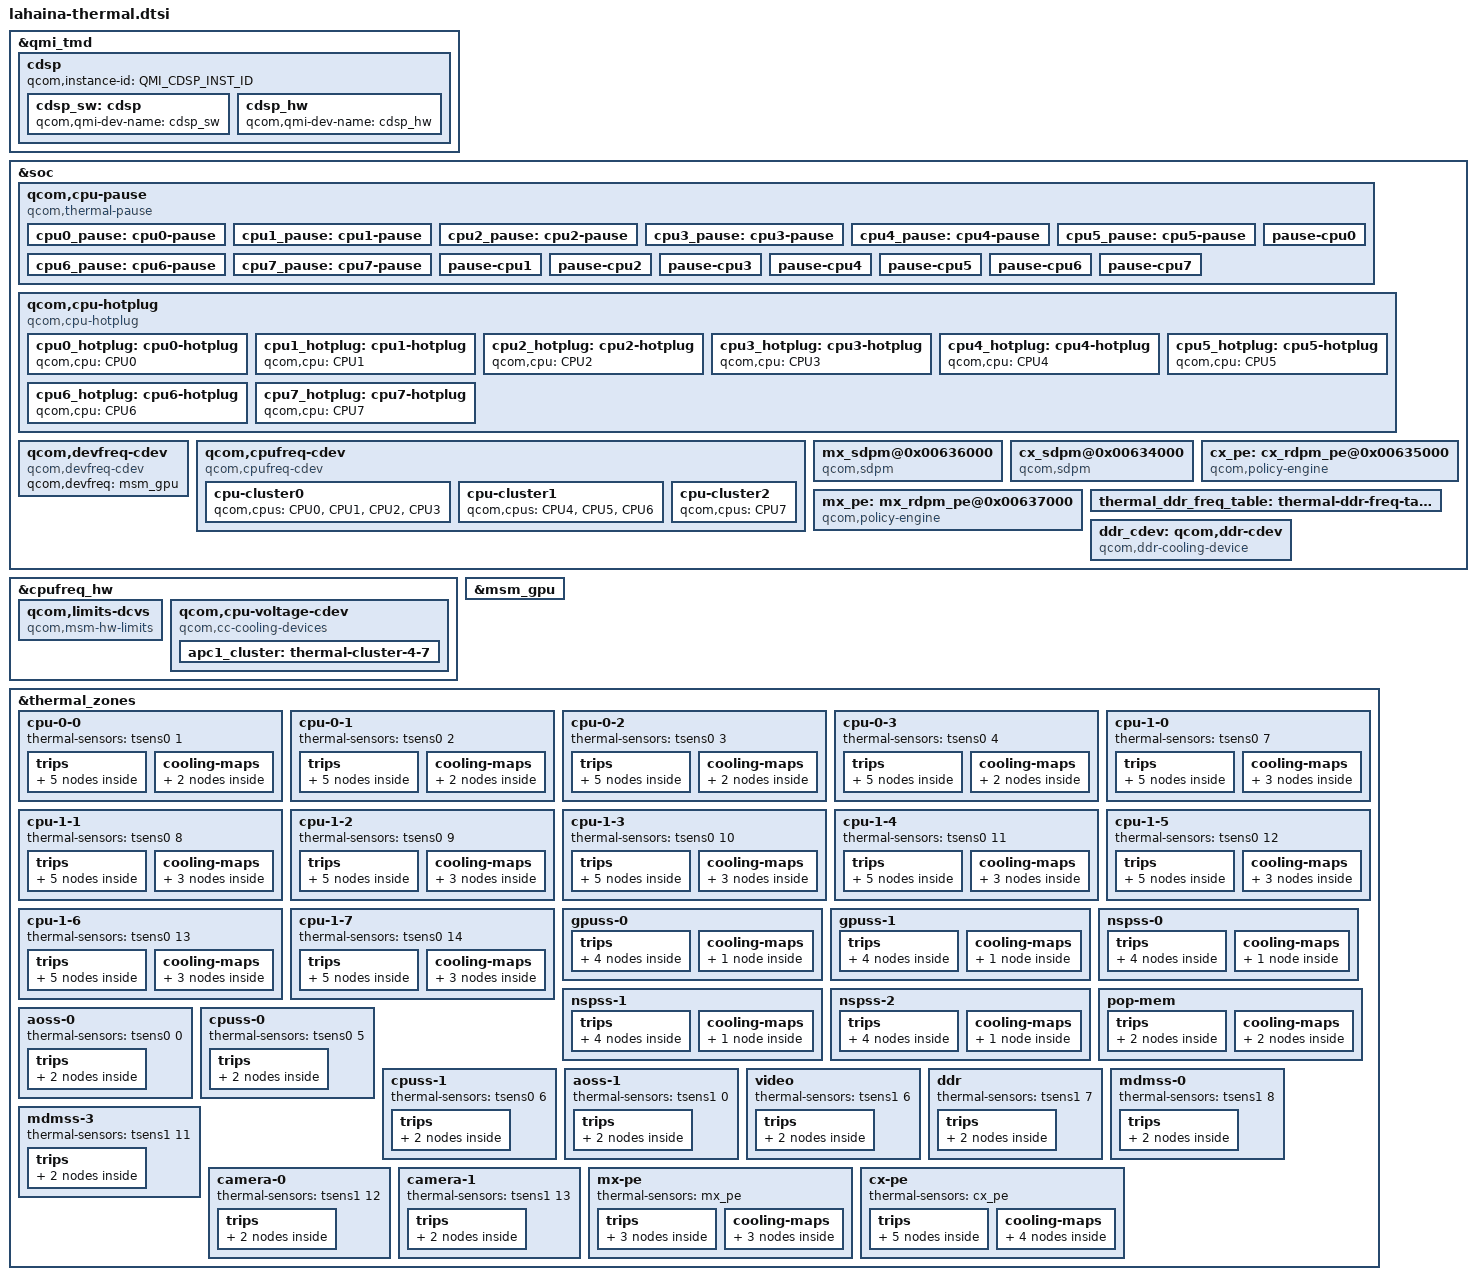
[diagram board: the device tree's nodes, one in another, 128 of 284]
// SPDX-License-Identifier: BSD-3-Clause
/*
 * Copyright (c) Qualcomm Technologies, Inc. and/or its subsidiaries.
 */

#include <dt-bindings/thermal/thermal_qti.h>
#include "lahaina-thermal-modem.dtsi"

&qmi_tmd {
	cdsp {
		qcom,instance-id = <QMI_CDSP_INST_ID>;

		cdsp_sw: cdsp {
			qcom,qmi-dev-name = "cdsp_sw";
			#cooling-cells = <2>;
		};

		cdsp_hw: cdsp_hw {
			qcom,qmi-dev-name = "cdsp_hw";
			#cooling-cells = <2>;
		};
	};
};

&soc {
	qcom,cpu-pause {
		compatible = "qcom,thermal-pause";
		cpu0_pause: cpu0-pause {
			qcom,cpus = <&CPU0>;
			qcom,cdev-alias = "thermal-pause-1";
			#cooling-cells = <2>;
		};

		cpu1_pause: cpu1-pause {
			qcom,cpus = <&CPU1>;
			qcom,cdev-alias = "thermal-pause-2";
			#cooling-cells = <2>;
		};

		cpu2_pause: cpu2-pause {
			qcom,cpus = <&CPU2>;
			qcom,cdev-alias = "thermal-pause-4";
			#cooling-cells = <2>;
		};

		cpu3_pause: cpu3-pause {
			qcom,cpus = <&CPU3>;
			qcom,cdev-alias = "thermal-pause-8";
			#cooling-cells = <2>;
		};

		cpu4_pause: cpu4-pause {
			qcom,cpus = <&CPU4>;
			qcom,cdev-alias = "thermal-pause-10";
			#cooling-cells = <2>;
		};

		cpu5_pause: cpu5-pause {
			qcom,cpus = <&CPU5>;
			qcom,cdev-alias = "thermal-pause-20";
			#cooling-cells = <2>;
		};

		cpu6_pause: cpu6-pause {
			qcom,cpus = <&CPU6>;
			qcom,cdev-alias = "thermal-pause-40";
			#cooling-cells = <2>;
		};

		cpu7_pause: cpu7-pause {
			qcom,cpus = <&CPU7>;
			qcom,cdev-alias = "thermal-pause-80";
			#cooling-cells = <2>;
		};

		/* Thermal-engine cooling devices */
		pause-cpu0 {
			qcom,cpus = <&CPU0>;
			qcom,cdev-alias = "pause-cpu0";
		};

		pause-cpu1 {
			qcom,cpus = <&CPU1>;
			qcom,cdev-alias = "pause-cpu1";
		};

		pause-cpu2 {
			qcom,cpus = <&CPU2>;
			qcom,cdev-alias = "pause-cpu2";
		};

		pause-cpu3 {
			qcom,cpus = <&CPU3>;
			qcom,cdev-alias = "pause-cpu3";
		};

		pause-cpu4 {
			qcom,cpus = <&CPU4>;
			qcom,cdev-alias = "pause-cpu4";
		};

		pause-cpu5 {
			qcom,cpus = <&CPU5>;
			qcom,cdev-alias = "pause-cpu5";
		};

		pause-cpu6 {
			qcom,cpus = <&CPU6>;
			qcom,cdev-alias = "pause-cpu6";
		};

		pause-cpu7 {
			qcom,cpus = <&CPU7>;
			qcom,cdev-alias = "pause-cpu7";
		};
	};

	qcom,cpu-hotplug {
		compatible = "qcom,cpu-hotplug";
		cpu0_hotplug: cpu0-hotplug {
			qcom,cpu = <&CPU0>;
			#cooling-cells = <2>;
		};

		cpu1_hotplug: cpu1-hotplug {
			qcom,cpu = <&CPU1>;
			#cooling-cells = <2>;
		};

		cpu2_hotplug: cpu2-hotplug {
			qcom,cpu = <&CPU2>;
			#cooling-cells = <2>;
		};

		cpu3_hotplug: cpu3-hotplug {
			qcom,cpu = <&CPU3>;
			#cooling-cells = <2>;
		};

		cpu4_hotplug: cpu4-hotplug {
			qcom,cpu = <&CPU4>;
			#cooling-cells = <2>;
		};

		cpu5_hotplug: cpu5-hotplug {
			qcom,cpu = <&CPU5>;
			#cooling-cells = <2>;
		};

		cpu6_hotplug: cpu6-hotplug {
			qcom,cpu = <&CPU6>;
			#cooling-cells = <2>;
		};

		cpu7_hotplug: cpu7-hotplug {
			qcom,cpu = <&CPU7>;
			#cooling-cells = <2>;
		};
	};

	qcom,devfreq-cdev {
		compatible = "qcom,devfreq-cdev";
		qcom,devfreq = <&msm_gpu>;
	};

	qcom,cpufreq-cdev {
		compatible = "qcom,cpufreq-cdev";
		cpu-cluster0 {
			qcom,cpus = <&CPU0 &CPU1 &CPU2 &CPU3>;
		};

		cpu-cluster1 {
			qcom,cpus = <&CPU4 &CPU5 &CPU6>;
		};

		cpu-cluster2 {
			qcom,cpus = <&CPU7>;
		};
	};

	mx_sdpm@0x00636000 {
		compatible = "qcom,sdpm";
		reg = <0x00636000 0x1000>;
		clock-names = "cam_cc_ipe", "video_cc_mvs0", "gcc_gp1";
		clocks = <&camcc CAM_CC_IPE_0_CLK_SRC>,
			<&videocc VIDEO_CC_MVS0_CLK_SRC>,
			<&gcc GCC_GP1_CLK_SRC>;
		cam_cc_ipe-supply = <&cam_cc_ipe_0_gdsc>;
		video_cc_mvs0-supply = <&video_cc_mvs0_gdsc>;
		csr-id = <1 3 5>;
	};

	cx_sdpm@0x00634000 {
		compatible = "qcom,sdpm";
		reg = <0x00634000 0x1000>;
		clock-names = "cam_cc_csi0phytiimer", "ufs_phy";
		clocks = <&camcc CAM_CC_CSI0PHYTIMER_CLK_SRC>,
			<&gcc GCC_UFS_PHY_AXI_CLK_SRC>;
		cam_cc_csi0phytiimer-supply = <&cam_cc_ipe_0_gdsc>;
		csr-id = <5 7>;
	};

	mx_pe: mx_rdpm_pe@0x00637000 {
		compatible = "qcom,policy-engine";
		#thermal-sensor-cells = <0>;
		reg = <0x00637000 0x1000>;
		interrupts = <GIC_SPI 237 IRQ_TYPE_LEVEL_HIGH>;
	};

	cx_pe: cx_rdpm_pe@0x00635000 {
		compatible = "qcom,policy-engine";
		#thermal-sensor-cells = <0>;
		reg = <0x00635000 0x1000>;
		interrupts = <GIC_SPI 243 IRQ_TYPE_LEVEL_HIGH>;
	};

	thermal_ddr_freq_table: thermal-ddr-freq-table {
		qcom,freq-tbl = <0>,
				<1720000>,
				<2086000>,
				<2597000>,
				<2929000>,
				<3879000>,
				<5161000>,
				<5931000>,
				<6515000>,
				<7980000>,
				<8136000>,
				<10437000>,
				<12191000>;
	};

	ddr_cdev: qcom,ddr-cdev {
		compatible = "qcom,ddr-cooling-device";
		#cooling-cells = <2>;
		qcom,bus-width = <4>;
		qcom,freq-table = <&thermal_ddr_freq_table>;
		interconnects = <&mc_virt MASTER_LLCC &mc_virt SLAVE_EBI1>;
	};
};

&cpufreq_hw {
	qcom,limits-dcvs {
		compatible = "qcom,msm-hw-limits";
		isens_vref_0p8-supply = <&pm8350_l5_ao>;
		isens-vref-0p8-settings = <880000 880000 30000>;
		isens_vref_1p8-supply = <&pm8350c_l1_ao>;
		isens-vref-1p8-settings = <1800000 1800000 20000>;
	};

	qcom,cpu-voltage-cdev {
		compatible = "qcom,cc-cooling-devices";
		apc1_cluster: thermal-cluster-4-7 {
			qcom,cluster0 = <&CPU4 &CPU5 &CPU6>;
			qcom,cluster1 = <&CPU7>;
			#cooling-cells = <2>;
		};
	};
};

&msm_gpu {
	#cooling-cells = <2>;
};

&thermal_zones {
	cpu-0-0 {
		thermal-sensors = <&tsens0 1>;
		trips {
			active-config0 {
				temperature = <125000>;
				hysteresis = <1000>;
				type = "passive";
			};

			thermal-hal-config {
				temperature = <95000>;
				hysteresis = <5000>;
				type = "passive";
			};

			cpu00_config: cpu00-config {
				temperature = <110000>;
				hysteresis = <10000>;
				type = "passive";
			};

			cpu00_config1: cpu00-config1 {
				temperature = <112000>;
				hysteresis = <12000>;
				type = "passive";
			};

			reset-mon-cfg {
				temperature = <115000>;
				hysteresis = <0>;
				type = "hot";
			};
		};

		cooling-maps {
			cpu00_cdev {
				trip = <&cpu00_config>;
				cooling-device = <&cpu0_pause 0 1>;
			};

			cpu00_cdev2 {
				trip = <&cpu00_config1>;
				cooling-device = <&cpu0_hotplug 0 1>;
			};
		};
	};

	cpu-0-1 {
		thermal-sensors = <&tsens0 2>;
		trips {
			active-config0 {
				temperature = <125000>;
				hysteresis = <1000>;
				type = "passive";
			};

			thermal-hal-config {
				temperature = <95000>;
				hysteresis = <5000>;
				type = "passive";
			};

			cpu01_config: cpu01-config {
				temperature = <110000>;
				hysteresis = <10000>;
				type = "passive";
			};

			cpu01_config1: cpu01-config1 {
				temperature = <112000>;
				hysteresis = <12000>;
				type = "passive";
			};

			reset-mon-cfg {
				temperature = <115000>;
				hysteresis = <0>;
				type = "hot";
			};
		};

		cooling-maps {
			cpu01_cdev {
				trip = <&cpu01_config>;
				cooling-device = <&cpu1_pause 0 1>;
			};

			cpu01_cdev2 {
				trip = <&cpu01_config1>;
				cooling-device = <&cpu1_hotplug 0 1>;
			};
		};
	};

	cpu-0-2 {
		thermal-sensors = <&tsens0 3>;
		trips {
			active-config0 {
				temperature = <125000>;
				hysteresis = <1000>;
				type = "passive";
			};

			thermal-hal-config {
				temperature = <95000>;
				hysteresis = <5000>;
				type = "passive";
			};

			cpu02_config: cpu02-config {
				temperature = <110000>;
				hysteresis = <10000>;
				type = "passive";
			};

			cpu02_config1: cpu02-config1 {
				temperature = <112000>;
				hysteresis = <12000>;
				type = "passive";
			};

			reset-mon-cfg {
				temperature = <115000>;
				hysteresis = <0>;
				type = "hot";
			};
		};

		cooling-maps {
			cpu02_cdev {
				trip = <&cpu02_config>;
				cooling-device = <&cpu2_pause 0 1>;
			};

			cpu02_cdev2 {
				trip = <&cpu02_config1>;
				cooling-device = <&cpu2_hotplug 0 1>;
			};
		};
	};

	cpu-0-3 {
		thermal-sensors = <&tsens0 4>;
		trips {
			active-config0 {
				temperature = <125000>;
				hysteresis = <1000>;
				type = "passive";
			};

			thermal-hal-config {
				temperature = <95000>;
				hysteresis = <5000>;
				type = "passive";
			};

			cpu03_config: cpu03-config {
				temperature = <110000>;
				hysteresis = <10000>;
				type = "passive";
			};

			cpu03_config1: cpu03-config1 {
				temperature = <112000>;
				hysteresis = <12000>;
				type = "passive";
			};

			reset-mon-cfg {
				temperature = <115000>;
				hysteresis = <0>;
				type = "hot";
			};
		};

		cooling-maps {
			cpu03_cdev {
				trip = <&cpu03_config>;
				cooling-device = <&cpu3_pause 0 1>;
			};

			cpu03_cdev2 {
				trip = <&cpu03_config1>;
				cooling-device = <&cpu3_hotplug 0 1>;
			};
		};
	};

	cpu-1-0 {
		thermal-sensors = <&tsens0 7>;
		trips {
			active-config0 {
				temperature = <125000>;
				hysteresis = <1000>;
				type = "passive";
			};

			thermal-hal-config {
				temperature = <95000>;
				hysteresis = <5000>;
				type = "passive";
			};

			cpu10_config: cpu10-config {
				temperature = <108000>;
				hysteresis = <8000>;
				type = "passive";
			};

			cpu10_config1: cpu10-config1 {
				temperature = <110000>;
				hysteresis = <10000>;
				type = "passive";
			};

			reset-mon-cfg {
				temperature = <115000>;
				hysteresis = <0>;
				type = "hot";
			};
		};

		cooling-maps {
			cpu10_cdev {
				trip = <&cpu10_config>;
				cooling-device = <&cpu4_pause 0 1>;
			};

			cpu10_cdev1 {
				trip = <&cpu10_config>;
				cooling-device = <&CPU4 0 THERMAL_NO_LIMIT>;
			};

			cpu10_cdev2 {
				trip = <&cpu10_config1>;
				cooling-device = <&cpu4_hotplug 1 1>;
			};
		};
	};

	cpu-1-1 {
		thermal-sensors = <&tsens0 8>;
		trips {
			active-config0 {
				temperature = <125000>;
				hysteresis = <1000>;
				type = "passive";
			};

			thermal-hal-config {
				temperature = <95000>;
				hysteresis = <5000>;
				type = "passive";
			};

			cpu11_config: cpu11-config {
				temperature = <108000>;
				hysteresis = <8000>;
				type = "passive";
			};

			cpu11_config1: cpu11-config1 {
				temperature = <110000>;
				hysteresis = <10000>;
				type = "passive";
			};

			reset-mon-cfg {
				temperature = <115000>;
				hysteresis = <0>;
				type = "hot";
			};
		};

		cooling-maps {
			cpu11_cdev {
				trip = <&cpu11_config>;
				cooling-device = <&cpu4_pause 0 1>;
			};

			cpu11_cdev1 {
				trip = <&cpu11_config>;
				cooling-device = <&CPU4 0 THERMAL_NO_LIMIT>;
			};

			cpu11_cdev2 {
				trip = <&cpu11_config1>;
				cooling-device = <&cpu4_hotplug 0 1>;
			};
		};
	};

	cpu-1-2 {
		thermal-sensors = <&tsens0 9>;
		trips {
			active-config0 {
				temperature = <125000>;
				hysteresis = <1000>;
				type = "passive";
			};

			thermal-hal-config {
				temperature = <95000>;
				hysteresis = <5000>;
				type = "passive";
			};

			cpu12_config: cpu12-config {
				temperature = <108000>;
				hysteresis = <8000>;
				type = "passive";
			};

			cpu12_config1: cpu12-config1 {
				temperature = <110000>;
				hysteresis = <10000>;
				type = "passive";
			};

			reset-mon-cfg {
				temperature = <115000>;
				hysteresis = <0>;
				type = "hot";
			};
		};

		cooling-maps {
			cpu12_cdev {
				trip = <&cpu12_config>;
				cooling-device = <&cpu5_pause 0 1>;
			};

			cpu12_cdev1 {
				trip = <&cpu12_config>;
				cooling-device = <&CPU4 0 THERMAL_NO_LIMIT>;
			};

			cpu12_cdev2 {
				trip = <&cpu12_config1>;
				cooling-device = <&cpu5_hotplug 0 1>;
			};
		};
	};

	cpu-1-3 {
		thermal-sensors = <&tsens0 10>;
		trips {
			active-config0 {
				temperature = <125000>;
				hysteresis = <1000>;
				type = "passive";
			};

			thermal-hal-config {
				temperature = <95000>;
				hysteresis = <5000>;
				type = "passive";
			};

			cpu13_config: cpu13-config {
				temperature = <108000>;
				hysteresis = <8000>;
				type = "passive";
			};

			cpu13_config1: cpu13-config1 {
				temperature = <110000>;
				hysteresis = <10000>;
				type = "passive";
			};

			reset-mon-cfg {
				temperature = <115000>;
				hysteresis = <0>;
				type = "hot";
			};
		};

		cooling-maps {
			cpu13_cdev {
				trip = <&cpu13_config>;
				cooling-device = <&cpu5_pause 0 1>;
			};

			cpu13_cdev1 {
				trip = <&cpu13_config>;
				cooling-device = <&CPU4 0 THERMAL_NO_LIMIT>;
			};

			cpu13_cdev2 {
				trip = <&cpu13_config1>;
				cooling-device = <&cpu5_hotplug 0 1>;
			};
		};
	};

	cpu-1-4 {
		thermal-sensors = <&tsens0 11>;
		trips {
			active-config0 {
				temperature = <125000>;
				hysteresis = <1000>;
				type = "passive";
			};

			thermal-hal-config {
				temperature = <95000>;
				hysteresis = <5000>;
				type = "passive";
			};

			cpu14_config: cpu14-config {
				temperature = <108000>;
				hysteresis = <8000>;
				type = "passive";
			};

			cpu14_config1: cpu14-config1 {
				temperature = <110000>;
				hysteresis = <10000>;
				type = "passive";
			};

			reset-mon-cfg {
				temperature = <115000>;
				hysteresis = <0>;
				type = "hot";
			};
		};

		cooling-maps {
			cpu14_cdev {
				trip = <&cpu14_config>;
				cooling-device = <&cpu6_pause 0 1>;
			};

			cpu14_cdev1 {
				trip = <&cpu14_config>;
				cooling-device = <&CPU4 0 THERMAL_NO_LIMIT>;
			};

			cpu14_cdev2 {
				trip = <&cpu14_config1>;
				cooling-device = <&cpu6_hotplug 0 1>;
			};
		};
	};

	cpu-1-5 {
		thermal-sensors = <&tsens0 12>;
		trips {
			active-config0 {
				temperature = <125000>;
				hysteresis = <1000>;
				type = "passive";
			};

			thermal-hal-config {
				temperature = <95000>;
				hysteresis = <5000>;
				type = "passive";
			};

			cpu15_config: cpu15-config {
				temperature = <108000>;
				hysteresis = <8000>;
				type = "passive";
			};

			cpu15_config1: cpu15-config1 {
				temperature = <110000>;
				hysteresis = <10000>;
				type = "passive";
			};

			reset-mon-cfg {
				temperature = <115000>;
				hysteresis = <0>;
				type = "hot";
			};
		};

		cooling-maps {
			cpu15_cdev {
				trip = <&cpu15_config>;
				cooling-device = <&cpu6_pause 0 1>;
			};

			cpu15_cdev1 {
				trip = <&cpu15_config>;
				cooling-device = <&CPU4 0 THERMAL_NO_LIMIT>;
			};

			cpu15_cdev2 {
				trip = <&cpu15_config1>;
				cooling-device = <&cpu6_hotplug 0 1>;
			};
		};
	};

	cpu-1-6 {
		thermal-sensors = <&tsens0 13>;
		trips {
			active-config0 {
				temperature = <125000>;
				hysteresis = <1000>;
				type = "passive";
			};

			thermal-hal-config {
				temperature = <95000>;
				hysteresis = <5000>;
				type = "passive";
			};

			cpu16_config: cpu16-config {
				temperature = <108000>;
				hysteresis = <8000>;
				type = "passive";
			};

			cpu16_config1: cpu16-config1 {
				temperature = <110000>;
				hysteresis = <10000>;
				type = "passive";
			};

			reset-mon-cfg {
				temperature = <115000>;
				hysteresis = <0>;
				type = "hot";
			};
		};

		cooling-maps {
			cpu16_cdev {
				trip = <&cpu16_config>;
				cooling-device = <&cpu7_pause 0 1>;
			};

			cpu16_cdev1 {
				trip = <&cpu16_config>;
				cooling-device = <&CPU7 0 THERMAL_NO_LIMIT>;
			};

			cpu16_cdev2 {
				trip = <&cpu16_config1>;
				cooling-device = <&cpu7_hotplug 0 1>;
			};
		};
	};

	cpu-1-7 {
		thermal-sensors = <&tsens0 14>;
		trips {
			active-config0 {
				temperature = <125000>;
				hysteresis = <1000>;
				type = "passive";
			};

			thermal-hal-config {
				temperature = <95000>;
				hysteresis = <5000>;
				type = "passive";
			};

			cpu17_config: cpu17-config {
				temperature = <108000>;
				hysteresis = <8000>;
				type = "passive";
			};

			cpu17_config1: cpu17-config1 {
				temperature = <110000>;
				hysteresis = <10000>;
				type = "passive";
			};

			reset-mon-cfg {
				temperature = <115000>;
				hysteresis = <0>;
				type = "hot";
			};
		};

		cooling-maps {
			cpu17_cdev {
				trip = <&cpu17_config>;
				cooling-device = <&cpu7_pause 0 1>;
			};

			cpu17_cdev1 {
				trip = <&cpu17_config>;
				cooling-device = <&CPU7 0 THERMAL_NO_LIMIT>;
			};

			cpu17_cdev2 {
				trip = <&cpu17_config1>;
				cooling-device = <&cpu7_hotplug 0 1>;
			};
		};
	};

	gpuss-0 {
		polling-delay-passive = <10>;
		thermal-sensors = <&tsens1 1>;
		trips {
			active-config0 {
				temperature = <125000>;
				hysteresis = <1000>;
				type = "passive";
			};

			thermal-hal-config {
				temperature = <95000>;
				hysteresis = <5000>;
				type = "passive";
			};

			gpuss0_config: gpuss0-trip0 {
				temperature = <95000>;
				hysteresis = <0>;
				type = "passive";
			};

			reset-mon-cfg {
				temperature = <115000>;
				hysteresis = <0>;
				type = "hot";
			};
		};

		cooling-maps {
			gpu_cdev {
				trip = <&gpuss0_config>;
				cooling-device = <&msm_gpu 0 THERMAL_NO_LIMIT>;
			};
		};
	};

	gpuss-1 {
		polling-delay-passive = <10>;
		thermal-sensors = <&tsens1 2>;
		trips {
			active-config0 {
				temperature = <125000>;
				hysteresis = <1000>;
				type = "passive";
			};

			thermal-hal-config {
				temperature = <95000>;
				hysteresis = <5000>;
				type = "passive";
			};

			gpuss1_config: gpuss1-trip0 {
				temperature = <95000>;
				hysteresis = <0>;
				type = "passive";
			};

			reset-mon-cfg {
				temperature = <115000>;
				hysteresis = <0>;
				type = "hot";
			};
		};

		cooling-maps {
			gpu_cdev {
				trip = <&gpuss1_config>;
				cooling-device = <&msm_gpu 0 THERMAL_NO_LIMIT>;
			};
		};
	};

	nspss-0 {
		polling-delay-passive = <10>;
		thermal-sensors = <&tsens1 3>;
		trips {
			active-config0 {
				temperature = <125000>;
				hysteresis = <1000>;
				type = "passive";
			};

			thermal-hal-config {
				temperature = <95000>;
				hysteresis = <5000>;
				type = "passive";
			};

			nspss0_config: nspss0-trip0 {
				temperature = <95000>;
				hysteresis = <0>;
				type = "passive";
			};

			reset-mon-cfg {
				temperature = <115000>;
				hysteresis = <0>;
				type = "hot";
			};
		};

		cooling-maps {
			nsp_cdev {
				trip = <&nspss0_config>;
				cooling-device = <&cdsp_sw 0 THERMAL_NO_LIMIT>;
			};
		};
	};

	nspss-1 {
		polling-delay-passive = <10>;
		thermal-sensors = <&tsens1 4>;
		trips {
			active-config0 {
				temperature = <125000>;
				hysteresis = <1000>;
				type = "passive";
			};

			thermal-hal-config {
				temperature = <95000>;
				hysteresis = <5000>;
				type = "passive";
			};

			nspss1_config: nspss1-trip0 {
				temperature = <95000>;
				hysteresis = <0>;
				type = "passive";
			};

			reset-mon-cfg {
				temperature = <115000>;
				hysteresis = <0>;
				type = "hot";
			};
		};

		cooling-maps {
			nsp_cdev {
				trip = <&nspss1_config>;
				cooling-device = <&cdsp_sw 0 THERMAL_NO_LIMIT>;
			};
		};
	};

	nspss-2 {
		polling-delay-passive = <10>;
		thermal-sensors = <&tsens1 5>;
		trips {
			active-config0 {
				temperature = <125000>;
				hysteresis = <1000>;
				type = "passive";
			};

			thermal-hal-config {
				temperature = <95000>;
				hysteresis = <5000>;
				type = "passive";
			};

			nspss2_config: nspss2-trip0 {
				temperature = <95000>;
				hysteresis = <0>;
				type = "passive";
			};

			reset-mon-cfg {
				temperature = <115000>;
				hysteresis = <0>;
				type = "hot";
			};
		};

		cooling-maps {
			nsp_cdev {
				trip = <&nspss2_config>;
				cooling-device = <&cdsp_sw 0 THERMAL_NO_LIMIT>;
			};
		};
	};

	pop-mem {
		polling-delay-passive = <10>;
		thermal-sensors = <&tsens1 7>;
		trips {
			pop_trip: pop-trip {
				temperature = <90000>;
				hysteresis = <0>;
				type = "passive";
			};

			pop_trip1: pop-trip1 {
				temperature = <90000>;
				hysteresis = <5000>;
				type = "passive";
			};
		};

		cooling-maps {
			pop_cdev {
				trip = <&pop_trip>;
				cooling-device =
					<&apc1_cluster 0 THERMAL_NO_LIMIT>;
			};

			pop_cdev1 {
				trip = <&pop_trip1>;
				cooling-device = <&ddr_cdev 0 5>;
			};
		};
	};

	aoss-0 {
		thermal-sensors = <&tsens0 0>;
		trips {
			active-config0 {
				temperature = <125000>;
				hysteresis = <1000>;
				type = "passive";
			};

			reset-mon-cfg {
				temperature = <115000>;
				hysteresis = <0>;
				type = "hot";
			};
		};
	};

	cpuss-0 {
		thermal-sensors = <&tsens0 5>;
		trips {
			active-config0 {
				temperature = <125000>;
				hysteresis = <1000>;
				type = "passive";
			};

			reset-mon-cfg {
				temperature = <115000>;
				hysteresis = <0>;
				type = "hot";
			};
		};
	};

	cpuss-1 {
		thermal-sensors = <&tsens0 6>;
		trips {
			active-config0 {
				temperature = <125000>;
				hysteresis = <1000>;
				type = "passive";
			};

			reset-mon-cfg {
				temperature = <115000>;
				hysteresis = <0>;
				type = "hot";
			};
		};
	};

	aoss-1 {
		thermal-sensors = <&tsens1 0>;
		trips {
			active-config0 {
				temperature = <125000>;
				hysteresis = <1000>;
				type = "passive";
			};

			reset-mon-cfg {
				temperature = <115000>;
				hysteresis = <0>;
				type = "hot";
			};
		};
	};

	video {
		thermal-sensors = <&tsens1 6>;
		trips {
			active-config0 {
				temperature = <125000>;
				hysteresis = <1000>;
				type = "passive";
			};

			reset-mon-cfg {
				temperature = <115000>;
				hysteresis = <0>;
				type = "hot";
			};
		};
	};

	ddr {
		thermal-sensors = <&tsens1 7>;
		trips {
			active-config0 {
				temperature = <125000>;
				hysteresis = <1000>;
				type = "passive";
			};

			reset-mon-cfg {
				temperature = <115000>;
				hysteresis = <0>;
				type = "hot";
			};
		};
	};

	mdmss-0 {
		thermal-sensors = <&tsens1 8>;
		trips {
			active-config0 {
				temperature = <125000>;
				hysteresis = <1000>;
				type = "passive";
			};

			reset-mon-cfg {
				temperature = <115000>;
				hysteresis = <0>;
				type = "hot";
			};
		};
	};

	mdmss-3 {
		thermal-sensors = <&tsens1 11>;
		trips {
			active-config0 {
				temperature = <125000>;
				hysteresis = <1000>;
				type = "passive";
			};

			reset-mon-cfg {
				temperature = <115000>;
				hysteresis = <0>;
				type = "hot";
			};
		};
	};

	camera-0 {
		thermal-sensors = <&tsens1 12>;
		trips {
			active-config0 {
				temperature = <125000>;
				hysteresis = <1000>;
				type = "passive";
			};

			reset-mon-cfg {
				temperature = <115000>;
				hysteresis = <0>;
				type = "hot";
			};
		};
	};

	camera-1 {
		thermal-sensors = <&tsens1 13>;
		trips {
			active-config0 {
				temperature = <125000>;
				hysteresis = <1000>;
				type = "passive";
			};

			reset-mon-cfg {
				temperature = <115000>;
				hysteresis = <0>;
				type = "hot";
			};
		};
	};

	mx-pe {
		thermal-sensors = <&mx_pe>;
		trips {
			mx_pe_config1: mx-pe-config1 {
				temperature = <1>;
				hysteresis = <1>;
				type = "passive";
			};

			mx_pe_config2: mx-pe-config2 {
				temperature = <2>;
				hysteresis = <1>;
				type = "passive";
			};

			mx_pe_config3: mx-pe-config3 {
				temperature = <3>;
				hysteresis = <1>;
				type = "passive";
			};
		};

		cooling-maps {
			mx_pe_cdev_1 {
				trip = <&mx_pe_config1>;
				cooling-device = <&cdsp_sw 0 1>;
			};

			mx_pe_cdev_2 {
				trip = <&mx_pe_config2>;
				cooling-device = <&msm_gpu 0 1>;
			};

			mx_pe_cdev_3 {
				trip = <&mx_pe_config3>;
				cooling-device = <&modem_tj 0 1>;
			};
		};
	};

	cx-pe {
		thermal-sensors = <&cx_pe>;
		trips {
			cx_pe_config1: cx-pe-config1 {
				temperature = <1>;
				hysteresis = <1>;
				type = "passive";
			};

			cx_pe_config2: cx-pe-config2 {
				temperature = <2>;
				hysteresis = <1>;
				type = "passive";
			};

			cx_pe_config3: cx-pe-config3 {
				temperature = <3>;
				hysteresis = <1>;
				type = "passive";
			};

			cx_pe_config4: cx-pe-config4 {
				temperature = <4>;
				hysteresis = <1>;
				type = "passive";
			};

			cx_pe_config5: cx-pe-config5 {
				temperature = <5>;
				hysteresis = <2>;
				type = "passive";
			};
		};

		cooling-maps {
			cx_pe_cdev_1 {
				trip = <&cx_pe_config1>;
				cooling-device = <&cdsp_sw 0 1>;
			};

			cx_pe_cdev_2 {
				trip = <&cx_pe_config2>;
				cooling-device = <&cdsp_sw 0 2>;
			};

			cx_pe_cdev_3 {
				trip = <&cx_pe_config3>;
				cooling-device = <&cdsp_sw 0 3>;
			};

			cx_pe_cdev_5 {
				trip = <&cx_pe_config5>;
				cooling-device = <&cdsp_sw 0 4>;
			};
		};
	};
};

